VERSION "created by canmatrix"

NS_ :

BS_:

BU_: User ADM_PC_LL25 ADM_PC_BC25 ADM_PC_BP25 ADM_PC_BI25

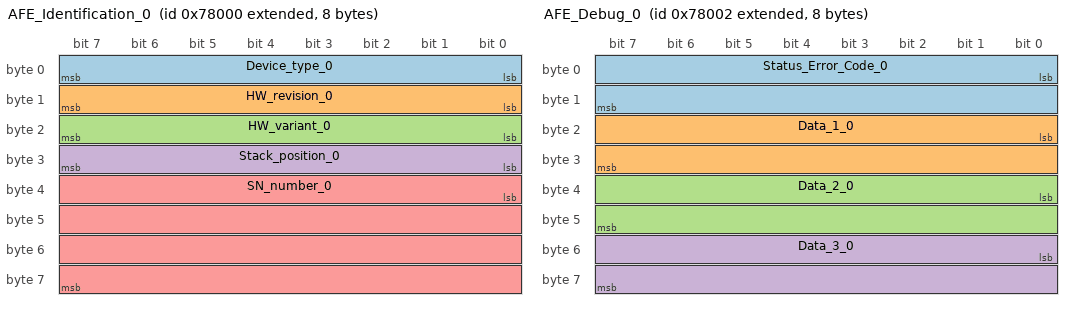
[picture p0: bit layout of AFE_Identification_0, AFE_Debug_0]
BO_ 2147975168 AFE_Identification_0: 8 ADM_PC_BP25
 SG_ Device_type_0 : 0|8@1+ (1,0) [0|255] "" Vector__XXX
 SG_ HW_revision_0 : 8|8@1+ (1,0) [0|255] "" Vector__XXX
 SG_ HW_variant_0 : 16|8@1+ (1,0) [0|255] "" Vector__XXX
 SG_ Stack_position_0 : 24|8@1+ (1,0) [0|255] "" Vector__XXX
 SG_ SN_number_0 : 32|32@1+ (1,0) [0|4294967295] "" Vector__XXX

BO_ 2147975169 AFE_FwInfo_0: 8 ADM_PC_BP25
 SG_ FW_info_mux_0 M : 56|8@1+ (1,0) [0|255] "" Vector__XXX
 SG_ FW_revision_0_0 m0 : 0|8@1+ (1,0) [0|255] "" Vector__XXX
 SG_ FW_revision_1_0 m0 : 8|8@1+ (1,0) [0|255] "" Vector__XXX
 SG_ FW_revision_2_0 m0 : 16|8@1+ (1,0) [0|255] "" Vector__XXX
 SG_ FW_revision_3_0 m0 : 24|8@1+ (1,0) [0|255] "" Vector__XXX
 SG_ FW_revision_4_0 m0 : 32|8@1+ (1,0) [0|255] "" Vector__XXX
 SG_ FW_revision_5_0 m0 : 40|8@1+ (1,0) [0|255] "" Vector__XXX
 SG_ FW_revision_6_0 m0 : 48|8@1+ (1,0) [0|255] "" Vector__XXX
 SG_ FW_revision_7_0 m1 : 0|8@1+ (1,0) [0|255] "" Vector__XXX
 SG_ FW_revision_8_0 m1 : 8|8@1+ (1,0) [0|255] "" Vector__XXX
 SG_ FW_revision_9_0 m1 : 16|8@1+ (1,0) [0|255] "" Vector__XXX
 SG_ FW_revision_10_0 m1 : 24|8@1+ (1,0) [0|255] "" Vector__XXX
 SG_ FW_revision_11_0 m1 : 32|8@1+ (1,0) [0|255] "" Vector__XXX
 SG_ FW_revision_12_0 m1 : 40|8@1+ (1,0) [0|255] "" Vector__XXX
 SG_ FW_revision_13_0 m1 : 48|8@1+ (1,0) [0|255] "" Vector__XXX
 SG_ FW_datecode_0_0 m2 : 0|8@1+ (1,0) [0|255] "" Vector__XXX
 SG_ FW_datecode_1_0 m2 : 8|8@1+ (1,0) [0|255] "" Vector__XXX
 SG_ FW_datecode_2_0 m2 : 16|8@1+ (1,0) [0|255] "" Vector__XXX
 SG_ FW_datecode_3_0 m2 : 24|8@1+ (1,0) [0|255] "" Vector__XXX
 SG_ FW_datecode_4_0 m2 : 32|8@1+ (1,0) [0|255] "" Vector__XXX
 SG_ FW_datecode_5_0 m2 : 40|8@1+ (1,0) [0|255] "" Vector__XXX
 SG_ FW_datecode_6_0 m2 : 48|8@1+ (1,0) [0|255] "" Vector__XXX
 SG_ FW_datecode_7_0 m3 : 0|8@1+ (1,0) [0|255] "" Vector__XXX
 SG_ FW_datecode_8_0 m3 : 8|8@1+ (1,0) [0|255] "" Vector__XXX
 SG_ FW_datecode_9_0 m3 : 16|8@1+ (1,0) [0|255] "" Vector__XXX
 SG_ FW_datecode_10_0 m3 : 24|8@1+ (1,0) [0|255] "" Vector__XXX
 SG_ FW_datecode_11_0 m3 : 32|8@1+ (1,0) [0|255] "" Vector__XXX
 SG_ FW_datecode_12_0 m3 : 40|8@1+ (1,0) [0|255] "" Vector__XXX
 SG_ FW_datecode_13_0 m3 : 48|8@1+ (1,0) [0|255] "" Vector__XXX

BO_ 2147975181 _AFE_Boot_FwInfo_0: 8 ADM_PC_BP25
 SG_ Boot_FW_info_mux_0 M : 56|8@1+ (1,0) [0|255] "" Vector__XXX
 SG_ FW_revision_0_0 m0 : 0|8@1+ (1,0) [0|255] "" Vector__XXX
 SG_ FW_revision_1_0 m0 : 8|8@1+ (1,0) [0|255] "" Vector__XXX
 SG_ FW_revision_2_0 m0 : 16|8@1+ (1,0) [0|255] "" Vector__XXX
 SG_ FW_revision_3_0 m0 : 24|8@1+ (1,0) [0|255] "" Vector__XXX
 SG_ FW_revision_4_0 m0 : 32|8@1+ (1,0) [0|255] "" Vector__XXX
 SG_ FW_revision_5_0 m0 : 40|8@1+ (1,0) [0|255] "" Vector__XXX
 SG_ FW_revision_6_0 m0 : 48|8@1+ (1,0) [0|255] "" Vector__XXX
 SG_ FW_revision_7_0 m1 : 0|8@1+ (1,0) [0|255] "" Vector__XXX
 SG_ FW_revision_8_0 m1 : 8|8@1+ (1,0) [0|255] "" Vector__XXX
 SG_ FW_revision_9_0 m1 : 16|8@1+ (1,0) [0|255] "" Vector__XXX
 SG_ FW_revision_10_0 m1 : 24|8@1+ (1,0) [0|255] "" Vector__XXX
 SG_ FW_revision_11_0 m1 : 32|8@1+ (1,0) [0|255] "" Vector__XXX
 SG_ FW_revision_12_0 m1 : 40|8@1+ (1,0) [0|255] "" Vector__XXX
 SG_ FW_revision_13_0 m1 : 48|8@1+ (1,0) [0|255] "" Vector__XXX
 SG_ FW_datecode_0_0 m2 : 0|8@1+ (1,0) [0|255] "" Vector__XXX
 SG_ FW_datecode_1_0 m2 : 8|8@1+ (1,0) [0|255] "" Vector__XXX
 SG_ FW_datecode_2_0 m2 : 16|8@1+ (1,0) [0|255] "" Vector__XXX
 SG_ FW_datecode_3_0 m2 : 24|8@1+ (1,0) [0|255] "" Vector__XXX
 SG_ FW_datecode_4_0 m2 : 32|8@1+ (1,0) [0|255] "" Vector__XXX
 SG_ FW_datecode_5_0 m2 : 40|8@1+ (1,0) [0|255] "" Vector__XXX
 SG_ FW_datecode_6_0 m2 : 48|8@1+ (1,0) [0|255] "" Vector__XXX
 SG_ FW_datecode_7_0 m3 : 0|8@1+ (1,0) [0|255] "" Vector__XXX
 SG_ FW_datecode_8_0 m3 : 8|8@1+ (1,0) [0|255] "" Vector__XXX
 SG_ FW_datecode_9_0 m3 : 16|8@1+ (1,0) [0|255] "" Vector__XXX
 SG_ FW_datecode_10_0 m3 : 24|8@1+ (1,0) [0|255] "" Vector__XXX
 SG_ FW_datecode_11_0 m3 : 32|8@1+ (1,0) [0|255] "" Vector__XXX
 SG_ FW_datecode_12_0 m3 : 40|8@1+ (1,0) [0|255] "" Vector__XXX
 SG_ FW_datecode_13_0 m3 : 48|8@1+ (1,0) [0|255] "" Vector__XXX

BO_ 2147975170 AFE_Debug_0: 8 ADM_PC_BP25
 SG_ Status_Error_Code_0 : 0|16@1+ (1,0) [0|65535] "" Vector__XXX
 SG_ Data_1_0 : 16|16@1+ (1,0) [0|65535] "" Vector__XXX
 SG_ Data_2_0 : 32|16@1+ (1,0) [0|65535] "" Vector__XXX
 SG_ Data_3_0 : 48|16@1+ (1,0) [0|65535] "" Vector__XXX

BO_ 2147975175 AFE_Status_0: 8 ADM_PC_BP25
 SG_ Running_0 : 0|1@1+ (1,0) [0|1] "" Vector__XXX
 SG_ PWM_0 : 1|1@1+ (1,0) [0|1] "" Vector__XXX
 SG_ Current_dc_loop_mode_0 : 2|1@1+ (1,0) [0|1] "" Vector__XXX
 SG_ Current_ac_loop_mode_0 : 3|1@1+ (1,0) [0|1] "" Vector__XXX
 SG_ Buck_0 : 5|1@1+ (1,0) [0|1] "" Vector__XXX
 SG_ Boost_0 : 6|1@1+ (1,0) [0|1] "" Vector__XXX
 SG_ Precharge_dc_buck_mode_0 : 7|1@1+ (1,0) [0|1] "" Vector__XXX
 SG_ Precharge_dc_boost_mode_0 : 8|1@1+ (1,0) [0|1] "" Vector__XXX
 SG_ Rectifier_3ph_0 : 9|1@1+ (1,0) [0|1] "" Vector__XXX
 SG_ Stack_mode_0 : 10|1@1+ (1,0) [0|1] "" Vector__XXX
 SG_ Master_0 : 11|1@1+ (1,0) [0|1] "" Vector__XXX
 SG_ Slave_0 : 12|1@1+ (1,0) [0|1] "" Vector__XXX
 SG_ Inverter_1ph_0 : 13|1@1+ (1,0) [0|1] "" Vector__XXX
 SG_ Boost_Neutral_0 : 14|1@1+ (1,0) [0|1] "" Vector__XXX
 SG_ Rectifier_1ph_0 : 15|1@1+ (1,0) [0|1] "" Vector__XXX
 SG_ Inverter_3ph_0 : 16|1@1+ (1,0) [0|1] "" Vector__XXX
 SG_ Ready_0 : 17|1@1+ (1,0) [0|1] "" Vector__XXX
 SG_ Inverter_1ph_Sync_0 : 18|1@1+ (1,0) [0|1] "" Vector__XXX
 SG_ Neutral_0 : 19|1@1+ (1,0) [0|1] "" Vector__XXX
 SG_ Rectifier_1ph_Buck_0 : 20|1@1+ (1,0) [0|1] "" Vector__XXX
 SG_ Inverter_1ph_Boost_0 : 21|1@1+ (1,0) [0|1] "" Vector__XXX
 SG_ Rectifier_distributed_0 : 22|1@1+ (1,0) [0|1] "" Vector__XXX
 SG_ MPPT_buck_0 : 23|1@1+ (1,0) [0|1] "" Vector__XXX
 SG_ MPPT_boost_0 : 24|1@1+ (1,0) [0|1] "" Vector__XXX
 SG_ Buck_2p_float_0 : 25|1@1+ (1,0) [0|1] "" Vector__XXX
 SG_ Inverter_1ph_Distributed_0 : 26|1@1+ (1,0) [0|1] "" Vector__XXX

BO_ 2147975174 AFE_Faults_0: 3 ADM_PC_BP25
 SG_ Protection_trip_internal_0 : 0|1@1+ (1,0) [0|1] "" Vector__XXX
 SG_ Protection_trip_external_0 : 1|1@1+ (1,0) [0|1] "" Vector__XXX
 SG_ Phase_U_overcurrent_0 : 2|1@1+ (1,0) [0|1] "" Vector__XXX
 SG_ Phase_U_overvoltage_0 : 3|1@1+ (1,0) [0|1] "" Vector__XXX
 SG_ Phase_U_undervoltage_0 : 4|1@1+ (1,0) [0|1] "" Vector__XXX
 SG_ Phase_V_overvoltage_0 : 5|1@1+ (1,0) [0|1] "" Vector__XXX
 SG_ Phase_V_undervoltage_0 : 6|1@1+ (1,0) [0|1] "" Vector__XXX
 SG_ Phase_V_overcurrent_0 : 7|1@1+ (1,0) [0|1] "" Vector__XXX
 SG_ Phase_W_overvoltage_0 : 8|1@1+ (1,0) [0|1] "" Vector__XXX
 SG_ Phase_W_undervoltage_0 : 9|1@1+ (1,0) [0|1] "" Vector__XXX
 SG_ Phase_W_overcurrent_0 : 10|1@1+ (1,0) [0|1] "" Vector__XXX
 SG_ DC_undervoltage_0 : 11|1@1+ (1,0) [0|1] "" Vector__XXX
 SG_ DC_overvoltage_0 : 12|1@1+ (1,0) [0|1] "" Vector__XXX
 SG_ MOSFET_overtemperature_0 : 13|1@1+ (1,0) [0|1] "" Vector__XXX
 SG_ Inductor_overtemperature_0 : 14|1@1+ (1,0) [0|1] "" Vector__XXX
 SG_ Keep_Alive_not_served_0 : 15|1@1+ (1,0) [0|1] "" Vector__XXX
 SG_ PLL_not_locked_0 : 16|1@1+ (1,0) [0|1] "" Vector__XXX
 SG_ NFO_0 : 20|1@1+ (1,0) [0|1] "" Vector__XXX
 SG_ Measurement_system_failure_0 : 21|1@1+ (1,0) [0|1] "" Vector__XXX
 SG_ EEPROM_failure_0 : 22|1@1+ (1,0) [0|1] "" Vector__XXX
 SG_ System_0 : 23|1@1+ (1,0) [0|1] "" Vector__XXX

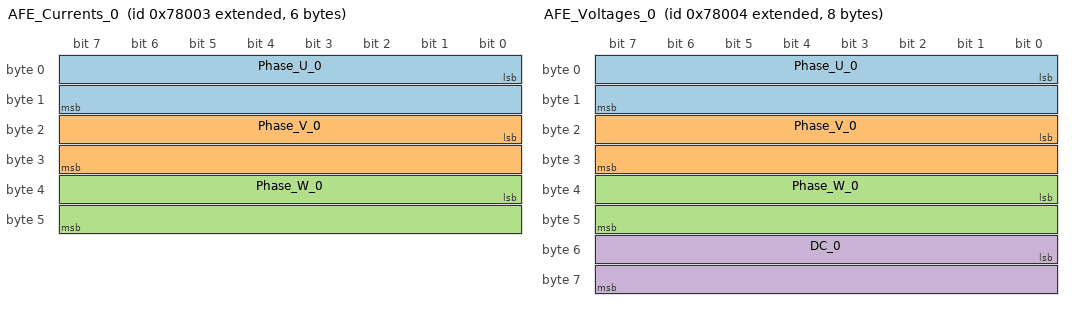
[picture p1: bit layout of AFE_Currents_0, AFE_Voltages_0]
BO_ 2147975171 AFE_Currents_0: 6 ADM_PC_BP25
 SG_ Phase_U_0 : 0|16@1- (0.01,0) [-327.68|327.67] "A" Vector__XXX
 SG_ Phase_V_0 : 16|16@1- (0.01,0) [-327.68|327.67] "A" Vector__XXX
 SG_ Phase_W_0 : 32|16@1- (0.01,0) [-327.68|327.67] "A" Vector__XXX

BO_ 2147975184 AFE_DC_Bus_current_0: 2 ADM_PC_BP25
 SG_ Bus_current_0 : 0|16@1- (0.01,0) [-327.68|327.67] "A" Vector__XXX

BO_ 2147975182 _AFE_Broadcast_0: 8 ADM_PC_BP25
 SG_ Diagnostics_Index_0 M : 56|8@1+ (1,0) [0|255] "" Vector__XXX
 SG_ Phase_U_0 m1 : 8|16@1- (0.01,0) [-327.68|327.67] "A" ADM_PC_BP25
 SG_ Phase_V_0 m1 : 24|16@1- (0.01,0) [-327.68|327.67] "A" ADM_PC_BP25
 SG_ Phase_W_0 m1 : 40|16@1- (0.01,0) [-327.68|327.67] "A" ADM_PC_BP25
 SG_ Stack_position_0 : 0|5@1+ (1,0) [0|31] "" ADM_PC_BP25
 SG_ Group_ID_0 : 5|3@1+ (1,0) [0|7] "" ADM_PC_BP25

BO_ 2147975172 AFE_Voltages_0: 8 ADM_PC_BP25
 SG_ Phase_U_0 : 0|16@1- (0.1,0) [-3276.8|3276.7] "V" Vector__XXX
 SG_ Phase_V_0 : 16|16@1- (0.1,0) [-3276.8|3276.7] "V" Vector__XXX
 SG_ Phase_W_0 : 32|16@1- (0.1,0) [-3276.8|3276.7] "V" Vector__XXX
 SG_ DC_0 : 48|16@1- (0.1,0) [-3276.8|3276.7] "V" Vector__XXX

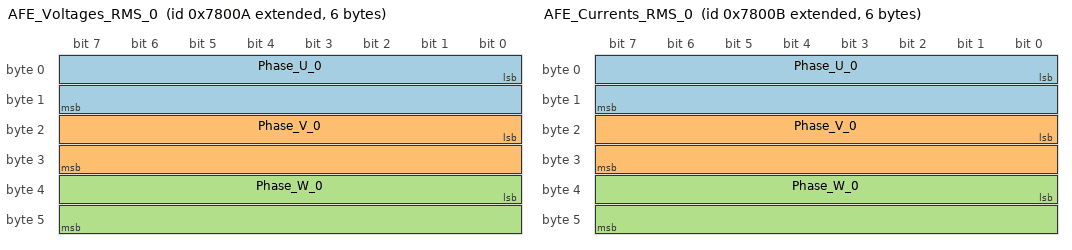
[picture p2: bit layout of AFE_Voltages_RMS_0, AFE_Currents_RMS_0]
BO_ 2147975178 AFE_Voltages_RMS_0: 6 ADM_PC_BP25
 SG_ Phase_U_0 : 0|16@1+ (0.1,0) [0|6553.5] "V" Vector__XXX
 SG_ Phase_V_0 : 16|16@1+ (0.1,0) [0|6553.5] "V" Vector__XXX
 SG_ Phase_W_0 : 32|16@1+ (0.1,0) [0|6553.5] "V" Vector__XXX

BO_ 2147975179 AFE_Currents_RMS_0: 6 ADM_PC_BP25
 SG_ Phase_U_0 : 0|16@1+ (0.01,0) [0.00|655.35] "A" Vector__XXX
 SG_ Phase_V_0 : 16|16@1+ (0.01,0) [0.00|655.35] "A" Vector__XXX
 SG_ Phase_W_0 : 32|16@1+ (0.01,0) [0.00|655.35] "A" Vector__XXX

BO_ 2147975180 AFE_Mains_0: 4 ADM_PC_BP25
 SG_ Frequency_0 : 0|16@1+ (0.01,0) [0.00|655.35] "Hz" Vector__XXX
 SG_ Phase_0 : 16|16@1- (0.1,0) [-3276.8|3276.7] "Deg." Vector__XXX

BO_ 2147975173 AFE_Temperatures_0: 4 ADM_PC_BP25
 SG_ Temp_Bridge_0 : 0|16@1- (0.01,0) [-327.68|327.67] "°C" Vector__XXX
 SG_ Temp_Inductors_0 : 16|16@1- (0.01,0) [-327.68|327.67] "°C" Vector__XXX

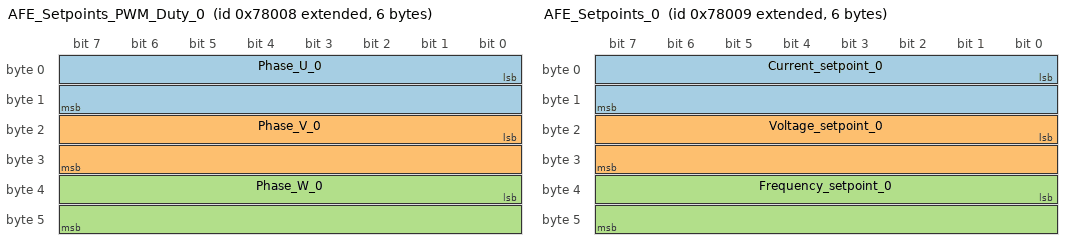
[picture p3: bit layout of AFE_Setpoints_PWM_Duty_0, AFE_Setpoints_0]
BO_ 2147975176 AFE_Setpoints_PWM_Duty_0: 6 ADM_PC_BP25
 SG_ Phase_U_0 : 0|16@1+ (0.001525902,0) [0E-009|99.999987570] "%" Vector__XXX
 SG_ Phase_V_0 : 16|16@1+ (0.001525902,0) [0E-009|99.999987570] "%" Vector__XXX
 SG_ Phase_W_0 : 32|16@1+ (0.001525902,0) [0E-009|99.999987570] "%" Vector__XXX

BO_ 2147975177 AFE_Setpoints_0: 6 ADM_PC_BP25
 SG_ Current_setpoint_0 : 0|16@1- (0.01,0) [-327.68|327.67] "A" Vector__XXX
 SG_ Voltage_setpoint_0 : 16|16@1+ (0.1,0) [0|6553.5] "V" Vector__XXX
 SG_ Frequency_setpoint_0 : 32|16@1+ (0.01,0) [0.00|655.35] "Hz" Vector__XXX

BO_ 2147942496 AFE_Keep_Alive_0: 1 User
 SG_ Keep_Alive_Enable_0 : 0|1@1+ (1,0) [0|1] "" ADM_PC_BP25

BO_ 2147942464 AFE_Mode_Control_0: 8 User
 SG_ Converter_ON_0 : 0|1@1+ (1,0) [0|1] "" ADM_PC_BP25
 SG_ PWM_ON_0 : 1|1@1+ (1,0) [0|1] "" ADM_PC_BP25
 SG_ DC_Current_feedback_ON_0 : 2|1@1+ (1,0) [0|1] "" ADM_PC_BP25
 SG_ AC_Current_feedback_ON_0 : 3|1@1+ (1,0) [0|1] "" ADM_PC_BP25
 SG_ Buck_ON_0 : 5|1@1+ (1,0) [0|1] "" ADM_PC_BP25
 SG_ Boost_ON_0 : 6|1@1+ (1,0) [0|1] "" ADM_PC_BP25
 SG_ Rectifier_3ph_ON_0 : 9|1@1+ (1,0) [0|1] "" ADM_PC_BP25
 SG_ Inverter_1ph_ON_0 : 10|1@1+ (1,0) [0|1] "" ADM_PC_BP25
 SG_ Rectifier_1ph_ON_0 : 11|1@1+ (1,0) [0|1] "" ADM_PC_BP25
 SG_ Boost_Neutral_ON_0 : 12|1@1+ (1,0) [0|1] "" ADM_PC_BP25
 SG_ Inverter_3ph_ON_0 : 13|1@1+ (1,0) [0|1] "" ADM_PC_BP25
 SG_ Inverter_1ph_Sync_ON_0 : 14|1@1+ (1,0) [0|1] "" ADM_PC_BP25
 SG_ Neutral_ON_0 : 15|1@1+ (1,0) [0|1] "" ADM_PC_BP25
 SG_ Rectifier_1ph_Buck_ON_0 : 16|1@1+ (1,0) [0|1] "" ADM_PC_BP25
 SG_ Inverter_1ph_Boost_ON_0 : 17|1@1+ (1,0) [0|1] "" ADM_PC_BP25
 SG_ Rectifier_Distributed_ON_0 : 18|1@1+ (1,0) [0|1] "" ADM_PC_BP25
 SG_ MPPT_buck_ON_0 : 19|1@1+ (1,0) [0|1] "" ADM_PC_BP25
 SG_ MPPT_boost_ON_0 : 20|1@1+ (1,0) [0|1] "" ADM_PC_BP25
 SG_ Buck_2p_float_ON_0 : 21|1@1+ (1,0) [0|1] "" ADM_PC_BP25
 SG_ Inverter_1ph_Distributed_ON_0 : 22|1@1+ (1,0) [0|1] "" ADM_PC_BP25

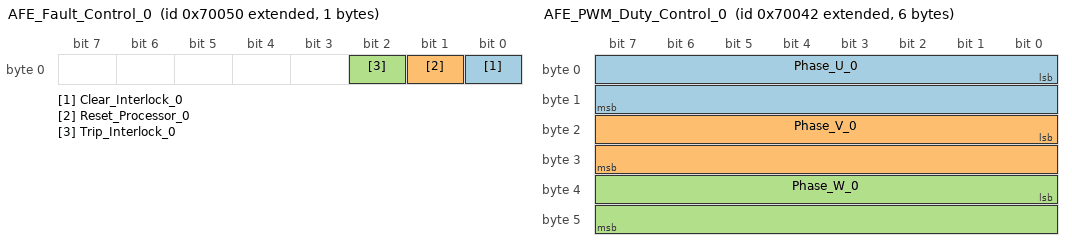
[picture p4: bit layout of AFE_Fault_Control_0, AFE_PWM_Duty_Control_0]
BO_ 2147942480 AFE_Fault_Control_0: 1 User
 SG_ Clear_Interlock_0 : 0|1@1+ (1,0) [0|1] "" ADM_PC_BP25
 SG_ Reset_Processor_0 : 1|1@1+ (1,0) [0|1] "" ADM_PC_BP25
 SG_ Trip_Interlock_0 : 2|1@1+ (1,0) [0|1] "" ADM_PC_BP25

BO_ 2147942465 AFE_Reactive_Current_Setpoint_Co: 2 User
 SG_ Reactive_current_setpoint_0 : 0|16@1- (0.01,0) [-150|150] "A" ADM_PC_BP25

BO_ 2147942466 AFE_PWM_Duty_Control_0: 6 User
 SG_ Phase_U_0 : 0|16@1+ (0.001525902,0) [0E-009|99.999987570] "%" ADM_PC_BP25
 SG_ Phase_V_0 : 16|16@1+ (0.001525902,0) [0E-009|99.999987570] "%" ADM_PC_BP25
 SG_ Phase_W_0 : 32|16@1+ (0.001525902,0) [0E-009|99.999987570] "%" ADM_PC_BP25

BO_ 2147942467 AFE_Current_Setpoint_Control_0: 2 User
 SG_ Current_setpoint_0 : 0|16@1- (0.01,0) [-150|150] "A" ADM_PC_BP25

BO_ 2147942468 AFE_Voltage_Setpoint_Control_0: 2 User
 SG_ Voltage_setpoint_0 : 0|16@1+ (0.1,0) [0|1500] "V" ADM_PC_BP25

BO_ 2147942472 AFE_Frequency_Setpoint_Control_0: 2 User
 SG_ Frequency_setpoint_0 : 0|16@1+ (0.01,0) [40|70] "Hz" ADM_PC_BP25

BO_ 2147942473 AFE_Phase_Setpoint_Control_0: 2 User
 SG_ Phase_setpoint_0 : 0|16@1+ (1,0) [0|360] "deg" ADM_PC_BP25

BO_ 2147942512 AFE_Rectifier_Setpoint_Control_0: 8 User
 SG_ Voltage_setpoint_2_0 : 0|16@1+ (0.1,0) [0|1500] "V" ADM_PC_BP25
 SG_ Current_setpoint_2_0 : 16|16@1- (0.01,0) [-150|150] "A" ADM_PC_BP25

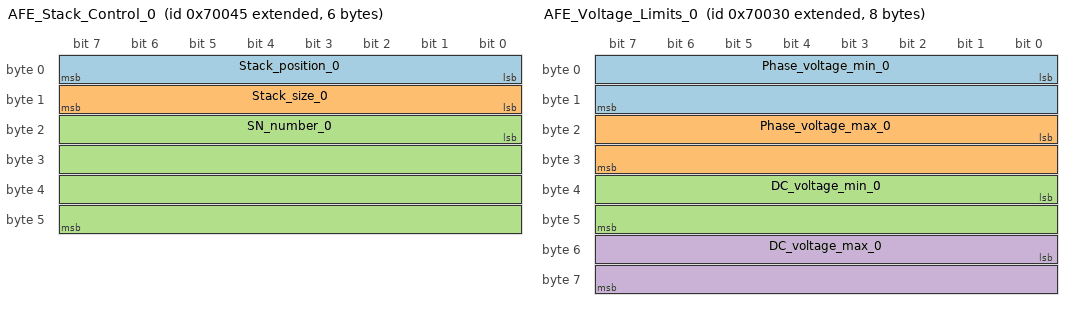
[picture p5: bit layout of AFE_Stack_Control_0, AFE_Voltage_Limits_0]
BO_ 2147942469 AFE_Stack_Control_0: 6 User
 SG_ Stack_position_0 : 0|8@1+ (1,0) [0|255] "" ADM_PC_BP25
 SG_ Stack_size_0 : 8|8@1+ (1,0) [0|255] "" ADM_PC_BP25
 SG_ SN_number_0 : 16|32@1+ (1,0) [0|4294967295] "" ADM_PC_BP25

BO_ 2147942448 AFE_Voltage_Limits_0: 8 User
 SG_ Phase_voltage_min_0 : 0|16@1- (0.1,0) [0|3276.7] "V" ADM_PC_BP25
 SG_ Phase_voltage_max_0 : 16|16@1- (0.1,0) [-3276.8|850] "V" ADM_PC_BP25
 SG_ DC_voltage_min_0 : 32|16@1- (0.1,0) [0|3276.7] "V" ADM_PC_BP25
 SG_ DC_voltage_max_0 : 48|16@1- (0.1,0) [-3276.8|850] "V" ADM_PC_BP25

BO_ 2147942449 AFE_Current_Limits_0: 4 User
 SG_ Phase_current_min_0 : 0|16@1- (0.01,0) [-60|60] "A" ADM_PC_BP25
 SG_ Phase_current_max_0 : 16|16@1- (0.01,0) [-60|60] "A" ADM_PC_BP25

BO_ 2147942476 AFE_Group_Control_0: 1 User
 SG_ Group_ID_0 : 0|8@1+ (1,0) [0|255] "" ADM_PC_BP25

BO_ 2147975183 AFE_Group_Info_0: 1 ADM_PC_BP25
 SG_ Group_ID_0 : 0|8@1+ (1,0) [0|255] "" Vector__XXX

BO_ 2147942497 AFE_System_Flags_Control_0: 8 User
 SG_ Factory_mode_0 : 0|1@1+ (1,0) [0|1] "" ADM_PC_BP25
 SG_ Silent_CAN_mode_0 : 1|1@1+ (1,0) [0|1] "" ADM_PC_BP25

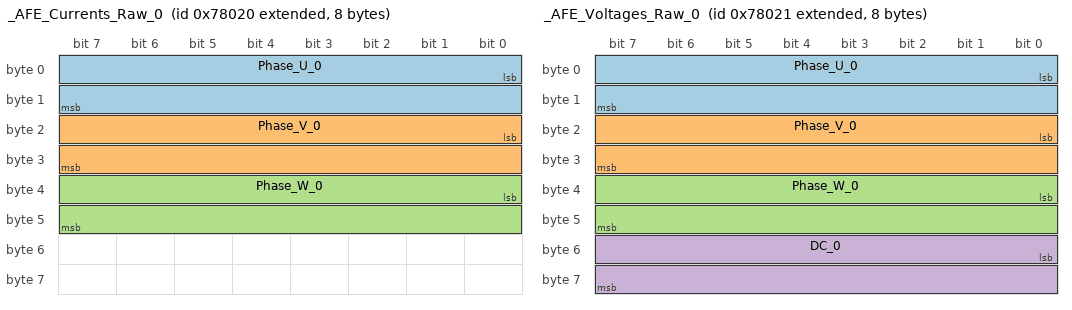
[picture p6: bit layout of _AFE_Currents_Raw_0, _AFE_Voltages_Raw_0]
BO_ 2147975200 _AFE_Currents_Raw_0: 8 ADM_PC_BP25
 SG_ Phase_U_0 : 0|16@1- (1,0) [-32768|32767] "" Vector__XXX
 SG_ Phase_V_0 : 16|16@1- (1,0) [-32768|32767] "" Vector__XXX
 SG_ Phase_W_0 : 32|16@1- (1,0) [-32768|32767] "" Vector__XXX

BO_ 2147975201 _AFE_Voltages_Raw_0: 8 ADM_PC_BP25
 SG_ Phase_U_0 : 0|16@1- (1,0) [-32768|32767] "" Vector__XXX
 SG_ Phase_V_0 : 16|16@1- (1,0) [-32768|32767] "" Vector__XXX
 SG_ Phase_W_0 : 32|16@1- (1,0) [-32768|32767] "" Vector__XXX
 SG_ DC_0 : 48|16@1- (1,0) [-32768|32767] "" Vector__XXX

BO_ 2147942474 _AFE_ADC_Calibration_Mode_0: 1 User
 SG_ Calibration_Index_0 M : 2|5@1+ (1,0) [0|31] "" Vector__XXX
 SG_ Current_U_0 m1 : 0|2@1+ (1,0) [0|3] "" ADM_PC_BP25
 SG_ Current_V_0 m2 : 0|2@1+ (1,0) [0|3] "" ADM_PC_BP25
 SG_ Current_W_0 m3 : 0|2@1+ (1,0) [0|3] "" ADM_PC_BP25
 SG_ Voltage_U_0 m4 : 0|2@1+ (1,0) [0|3] "" ADM_PC_BP25
 SG_ Voltage_V_0 m5 : 0|2@1+ (1,0) [0|3] "" ADM_PC_BP25
 SG_ Voltage_W_0 m6 : 0|2@1+ (1,0) [0|3] "" ADM_PC_BP25
 SG_ Voltage_DC_0 m7 : 0|2@1+ (1,0) [0|3] "" ADM_PC_BP25
 SG_ start_0 : 7|1@1+ (1,0) [0|1] "" ADM_PC_BP25

BO_ 2147942475 _AFE_ADC_Calibration_Setpoint_0: 3 User
 SG_ Calibration_Index_0 M : 16|5@1+ (1,0) [0|31] "" Vector__XXX
 SG_ Current_U_0 m1 : 0|16@1- (0.01,0) [-100|100] "A" ADM_PC_BP25
 SG_ Current_V_0 m2 : 0|16@1- (0.01,0) [-100|100] "A" ADM_PC_BP25
 SG_ Current_W_0 m3 : 0|16@1- (0.01,0) [-100|100] "A" ADM_PC_BP25
 SG_ Voltage_U_0 m4 : 0|16@1+ (0.1,0) [0|1500] "V" ADM_PC_BP25
 SG_ Voltage_V_0 m5 : 0|16@1+ (0.1,0) [0|1500] "V" ADM_PC_BP25
 SG_ Voltage_W_0 m6 : 0|16@1+ (0.1,0) [0|1500] "V" ADM_PC_BP25
 SG_ Voltage_DC_0 m7 : 0|16@1+ (0.1,0) [0|1500] "V" ADM_PC_BP25
 SG_ point_0 : 21|3@1+ (1,0) [0|7] "" ADM_PC_BP25

BO_ 2147942470 _AFE_Calibration_Offset_Update_0: 6 User
 SG_ Calibration_Index_0 M : 16|16@1+ (1,0) [0|65535] "" Vector__XXX
 SG_ Current_U_0 m0 : 0|16@1- (1,0) [-32768|32767] "ADC Counts" ADM_PC_BP25
 SG_ Current_V_0 m1 : 0|16@1- (1,0) [-32768|32767] "ADC Counts" ADM_PC_BP25
 SG_ Current_W_0 m2 : 0|16@1- (1,0) [-32768|32767] "ADC Counts" ADM_PC_BP25
 SG_ Voltage_U_0 m3 : 0|16@1- (1,0) [-32768|32767] "ADC Counts" ADM_PC_BP25
 SG_ Voltage_V_0 m4 : 0|16@1- (1,0) [-32768|32767] "ADC Counts" ADM_PC_BP25
 SG_ Voltage_W_0 m5 : 0|16@1- (1,0) [-32768|32767] "ADC Counts" ADM_PC_BP25
 SG_ Voltage_DC_0 m6 : 0|16@1- (1,0) [-32768|32767] "ADC Counts" ADM_PC_BP25
 SG_ CRC_0 : 32|16@1+ (1,0) [0|65535] "-" ADM_PC_BP25

BO_ 2147942471 _AFE_Calibration_Scale_Update_0: 6 User
 SG_ Calibration_Index_0 M : 16|16@1+ (1,0) [0|65535] "" Vector__XXX
 SG_ Current_U_0 m0 : 0|16@1- (0.0000152587890625,0) [-0.5000000000000000|0.4999847412109375] "scale = 1.0 + value" ADM_PC_BP25
 SG_ Current_V_0 m1 : 0|16@1- (0.0000152587890625,0) [-0.5000000000000000|0.4999847412109375] "scale = 1.0 + value" ADM_PC_BP25
 SG_ Current_W_0 m2 : 0|16@1- (0.0000152587890625,0) [-0.5000000000000000|0.4999847412109375] "scale = 1.0 + value" ADM_PC_BP25
 SG_ Voltage_U_0 m3 : 0|16@1- (0.0000152587890625,0) [-0.5000000000000000|0.4999847412109375] "scale = 1.0 + value" ADM_PC_BP25
 SG_ Voltage_V_0 m4 : 0|16@1- (0.0000152587890625,0) [-0.5000000000000000|0.4999847412109375] "scale = 1.0 + value" ADM_PC_BP25
 SG_ Voltage_W_0 m5 : 0|16@1- (0.0000152587890625,0) [-0.5000000000000000|0.4999847412109375] "scale = 1.0 + value" ADM_PC_BP25
 SG_ Voltage_DC_0 m6 : 0|16@1- (0.0000152587890625,0) [-0.5000000000000000|0.4999847412109375] "scale = 1.0 + value" ADM_PC_BP25
 SG_ CRC_0 : 32|16@1+ (1,0) [0|65535] "-" ADM_PC_BP25

BO_ 2147975249 _AFE_Calibration_Adc_Scale_0: 6 ADM_PC_BP25
 SG_ Adc_Index_0 M : 32|16@1+ (1,0) [0|65535] "" Vector__XXX
 SG_ Current_U_0 m0 : 0|32@1+ (1,0) [0|4294967295] "1 / adc_bins" User
 SG_ Current_V_0 m1 : 0|32@1+ (1,0) [0|4294967295] "1 / adc_bins" User
 SG_ Current_W_0 m2 : 0|32@1+ (1,0) [0|4294967295] "1 / adc_bins" User
 SG_ Voltage_U_0 m3 : 0|32@1+ (1,0) [0|4294967295] "1 / adc_bins" User
 SG_ Voltage_V_0 m4 : 0|32@1+ (1,0) [0|4294967295] "1 / adc_bins" User
 SG_ Voltage_W_0 m5 : 0|32@1+ (1,0) [0|4294967295] "1 / adc_bins" User
 SG_ Voltage_DC_0 m6 : 0|32@1+ (1,0) [0|4294967295] "1 / adc_bins" User

BO_ 2147975250 _AFE_Calibration_Adc_Fs_0: 6 ADM_PC_BP25
 SG_ Adc_Index_0 M : 32|16@1+ (1,0) [0|65535] "" Vector__XXX
 SG_ Current_U_0 m0 : 0|32@1+ (1,0) [0|4294967295] "Fullscale" User
 SG_ Current_V_0 m1 : 0|32@1+ (1,0) [0|4294967295] "Fullscale" User
 SG_ Current_W_0 m2 : 0|32@1+ (1,0) [0|4294967295] "Fullscale" User
 SG_ Voltage_U_0 m3 : 0|32@1+ (1,0) [0|4294967295] "Fullscale" User
 SG_ Voltage_V_0 m4 : 0|32@1+ (1,0) [0|4294967295] "Fullscale" User
 SG_ Voltage_W_0 m5 : 0|32@1+ (1,0) [0|4294967295] "Fullscale" User
 SG_ Voltage_DC_0 m6 : 0|32@1+ (1,0) [0|4294967295] "Fullscale" User

BO_ 2147975251 _AFE_Calibration_Adc_Offset_0: 4 ADM_PC_BP25
 SG_ Adc_Index_0 M : 16|16@1+ (1,0) [0|65535] "" Vector__XXX
 SG_ Current_U_0 m0 : 0|16@1- (1,0) [-32768|32767] "-" User
 SG_ Current_V_0 m1 : 0|16@1- (1,0) [-32768|32767] "-" User
 SG_ Current_W_0 m2 : 0|16@1- (1,0) [-32768|32767] "-" User
 SG_ Voltage_U_0 m3 : 0|16@1- (1,0) [-32768|32767] "-" User
 SG_ Voltage_V_0 m4 : 0|16@1- (1,0) [-32768|32767] "-" User
 SG_ Voltage_W_0 m5 : 0|16@1- (1,0) [-32768|32767] "-" User
 SG_ Voltage_DC_0 m6 : 0|16@1- (1,0) [-32768|32767] "-" User

BO_ 2147975252 _AFE_Calibration_Adc_Gain_0: 4 ADM_PC_BP25
 SG_ Adc_Index_0 M : 16|16@1+ (1,0) [0|65535] "" Vector__XXX
 SG_ Current_U_0 m0 : 0|16@1- (1,0) [-32768|32767] "-" User
 SG_ Current_V_0 m1 : 0|16@1- (1,0) [-32768|32767] "-" User
 SG_ Current_W_0 m2 : 0|16@1- (1,0) [-32768|32767] "-" User
 SG_ Voltage_U_0 m3 : 0|16@1- (1,0) [-32768|32767] "-" User
 SG_ Voltage_V_0 m4 : 0|16@1- (1,0) [-32768|32767] "-" User
 SG_ Voltage_W_0 m5 : 0|16@1- (1,0) [-32768|32767] "-" User
 SG_ Voltage_DC_0 m6 : 0|16@1- (1,0) [-32768|32767] "-" User

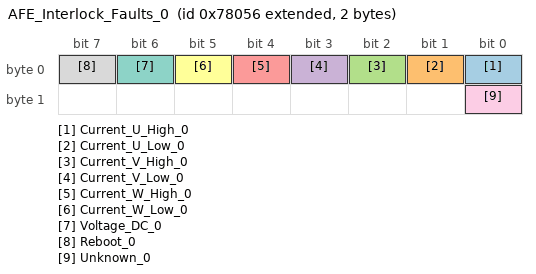
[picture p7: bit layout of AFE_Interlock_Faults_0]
BO_ 2147975254 AFE_Interlock_Faults_0: 2 ADM_PC_BP25
 SG_ Current_U_High_0 : 0|1@1+ (1,0) [0|1] "" Vector__XXX
 SG_ Current_U_Low_0 : 1|1@1+ (1,0) [0|1] "" Vector__XXX
 SG_ Current_V_High_0 : 2|1@1+ (1,0) [0|1] "" Vector__XXX
 SG_ Current_V_Low_0 : 3|1@1+ (1,0) [0|1] "" Vector__XXX
 SG_ Current_W_High_0 : 4|1@1+ (1,0) [0|1] "" Vector__XXX
 SG_ Current_W_Low_0 : 5|1@1+ (1,0) [0|1] "" Vector__XXX
 SG_ Voltage_DC_0 : 6|1@1+ (1,0) [0|1] "" Vector__XXX
 SG_ Reboot_0 : 7|1@1+ (1,0) [0|1] "" Vector__XXX
 SG_ Unknown_0 : 8|1@1+ (1,0) [0|1] "" Vector__XXX

BO_TX_BU_ 2147942464 : User,ADM_PC_LL25,ADM_PC_BC25,ADM_PC_BI25;
BO_TX_BU_ 2147942467 : User,ADM_PC_LL25,ADM_PC_BC25,ADM_PC_BI25;
BO_TX_BU_ 2147942468 : User,ADM_PC_LL25,ADM_PC_BC25,ADM_PC_BI25;
CM_ BO_ 2147975168  "Identification of the device";
CM_ BO_ 2147975169  "Git revision of the DSP firmware";
CM_ BO_ 2147975181  "Git revision of the bootloader firmware.";
CM_ BO_ 2147975170  "Values for debugging of HW/SW problems";
CM_ BO_ 2147975175  "Status bitfield";
CM_ BO_ 2147975174  "Fault bitfield";
CM_ BO_ 2147975171  "Current of phases U, V, W";
CM_ BO_ 2147975184  "Current of of the DC Bus";
CM_ BO_ 2147975182  "All AFEs will listen to this message";
CM_ BO_ 2147975179  "RMS Current of phases U, V, W";
CM_ BO_ 2147975180  "Three-Phase mains health (frequency, phase...)";
CM_ BO_ 2147975173  "Readouts of the module temperature sensors";
CM_ BO_ 2147975176  "Setpoints";
CM_ BO_ 2147975177  "Setpoints";
CM_ BO_ 2147942496  "Keep alive ping message. ";
CM_ BO_ 2147942464  "Operation Mode control: sets the converter operation mode";
CM_ BO_ 2147942480  "Fault Control: actions to clear faults and reset the system";
CM_ BO_ 2147942465  "Reactive power setpoint control.";
CM_ BO_ 2147942466  "PWM duty cycle control";
CM_ BO_ 2147942467  "Current setpoint control";
CM_ BO_ 2147942468  "Voltage setpoint control";
CM_ BO_ 2147942472  "Frequency setpoint control";
CM_ BO_ 2147942473  "Phase setpoint control";
CM_ BO_ 2147942512  "Additional voltage and current setpoints in single-phase rectifier and inverter control modes.";
CM_ BO_ 2147942469  "PFC stack control";
CM_ BO_ 2147942448  "Set the input and output voltage limits (minimum and maximum)";
CM_ BO_ 2147942449  "Set the output current limits (mminimum and maximum)";
CM_ BO_ 2147942476  "Set the Group ID of the device";
CM_ BO_ 2147975183  "Contains the Group ID of the device";
CM_ BO_ 2147942497  "Control the system flags";
CM_ BO_ 2147975200  "Current of phases A and B";
CM_ BO_ 2147975201  "Current of phases A and B";
CM_ BO_ 2147942474  "Automatic ADC calibration.";
CM_ BO_ 2147942475  "Setpoint for automatic ADC calibration.";
CM_ BO_ 2147942470  "Update of the calibration table for offsets.";
CM_ BO_ 2147942471  "Update of the calibration table for scales.";
CM_ BO_ 2147975249  "
                Adc scale (resolution) value of readouts.
            ";
CM_ BO_ 2147975250  "
                Adc fullscale value of readouts.
            ";
CM_ BO_ 2147975251  "
                Readout of ADC calibration data (offset) from EEPROM.
            ";
CM_ BO_ 2147975252  "
                Readout of ADC calibration data (gain) from EEPROM.
            ";
CM_ BO_ 2147975254  "Fault bitfield";

CM_ SG_ 2147975168 Device_type_0 "The device identification field, uniquely identifies the sender in the network";
CM_ SG_ 2147975168 HW_revision_0 "The hardware revision number";
CM_ SG_ 2147975168 HW_variant_0 "The DSP firmware revision number";
CM_ SG_ 2147975168 Stack_position_0 "Position of the module within the stack";
CM_ SG_ 2147975168 SN_number_0 "Unique module serial number";
CM_ SG_ 2147975169 FW_revision_0_0 "Character 0";
CM_ SG_ 2147975169 FW_revision_1_0 "Character 1";
CM_ SG_ 2147975169 FW_revision_2_0 "Character 2";
CM_ SG_ 2147975169 FW_revision_3_0 "Character 3";
CM_ SG_ 2147975169 FW_revision_4_0 "Character 3";
CM_ SG_ 2147975169 FW_revision_5_0 "Character 3";
CM_ SG_ 2147975169 FW_revision_6_0 "Character 3";
CM_ SG_ 2147975169 FW_revision_7_0 "Character 7";
CM_ SG_ 2147975169 FW_revision_8_0 "Character 8";
CM_ SG_ 2147975169 FW_revision_9_0 "Character 9";
CM_ SG_ 2147975169 FW_revision_10_0 "Character 10";
CM_ SG_ 2147975169 FW_revision_11_0 "Character 11";
CM_ SG_ 2147975169 FW_revision_12_0 "Character 12";
CM_ SG_ 2147975169 FW_revision_13_0 "Character 13";
CM_ SG_ 2147975169 FW_datecode_0_0 "Character 0";
CM_ SG_ 2147975169 FW_datecode_1_0 "Character 1";
CM_ SG_ 2147975169 FW_datecode_2_0 "Character 2";
CM_ SG_ 2147975169 FW_datecode_3_0 "Character 3";
CM_ SG_ 2147975169 FW_datecode_4_0 "Character 3";
CM_ SG_ 2147975169 FW_datecode_5_0 "Character 3";
CM_ SG_ 2147975169 FW_datecode_6_0 "Character 3";
CM_ SG_ 2147975169 FW_datecode_7_0 "Character 7";
CM_ SG_ 2147975169 FW_datecode_8_0 "Character 8";
CM_ SG_ 2147975169 FW_datecode_9_0 "Character 9";
CM_ SG_ 2147975169 FW_datecode_10_0 "Character 10";
CM_ SG_ 2147975169 FW_datecode_11_0 "Character 11";
CM_ SG_ 2147975169 FW_datecode_12_0 "Character 12";
CM_ SG_ 2147975169 FW_datecode_13_0 "Character 13";
CM_ SG_ 2147975181 FW_revision_0_0 "Character 0";
CM_ SG_ 2147975181 FW_revision_1_0 "Character 1";
CM_ SG_ 2147975181 FW_revision_2_0 "Character 2";
CM_ SG_ 2147975181 FW_revision_3_0 "Character 3";
CM_ SG_ 2147975181 FW_revision_4_0 "Character 3";
CM_ SG_ 2147975181 FW_revision_5_0 "Character 3";
CM_ SG_ 2147975181 FW_revision_6_0 "Character 3";
CM_ SG_ 2147975181 FW_revision_7_0 "Character 7";
CM_ SG_ 2147975181 FW_revision_8_0 "Character 8";
CM_ SG_ 2147975181 FW_revision_9_0 "Character 9";
CM_ SG_ 2147975181 FW_revision_10_0 "Character 10";
CM_ SG_ 2147975181 FW_revision_11_0 "Character 11";
CM_ SG_ 2147975181 FW_revision_12_0 "Character 12";
CM_ SG_ 2147975181 FW_revision_13_0 "Character 13";
CM_ SG_ 2147975181 FW_datecode_0_0 "Character 0";
CM_ SG_ 2147975181 FW_datecode_1_0 "Character 1";
CM_ SG_ 2147975181 FW_datecode_2_0 "Character 2";
CM_ SG_ 2147975181 FW_datecode_3_0 "Character 3";
CM_ SG_ 2147975181 FW_datecode_4_0 "Character 3";
CM_ SG_ 2147975181 FW_datecode_5_0 "Character 3";
CM_ SG_ 2147975181 FW_datecode_6_0 "Character 3";
CM_ SG_ 2147975181 FW_datecode_7_0 "Character 7";
CM_ SG_ 2147975181 FW_datecode_8_0 "Character 8";
CM_ SG_ 2147975181 FW_datecode_9_0 "Character 9";
CM_ SG_ 2147975181 FW_datecode_10_0 "Character 10";
CM_ SG_ 2147975181 FW_datecode_11_0 "Character 11";
CM_ SG_ 2147975181 FW_datecode_12_0 "Character 12";
CM_ SG_ 2147975181 FW_datecode_13_0 "Character 13";
CM_ SG_ 2147975170 Status_Error_Code_0 "Main status / error code as defined in errno/errno.h";
CM_ SG_ 2147975170 Data_1_0 "Additional information for the error/status";
CM_ SG_ 2147975170 Data_2_0 "Additional information for the error/status";
CM_ SG_ 2147975170 Data_3_0 "Additional information for the error/status";
CM_ SG_ 2147975175 Running_0 "Indicates if converter is running.";
CM_ SG_ 2147975175 PWM_0 "Indicates if converter is in PWM control mode.";
CM_ SG_ 2147975175 Current_dc_loop_mode_0 "Indicates if the current DC loop is enabled.";
CM_ SG_ 2147975175 Current_ac_loop_mode_0 "Indicates if the current AC loop is enabled.";
CM_ SG_ 2147975175 Buck_0 "Indicates if converter is in buck control mode.";
CM_ SG_ 2147975175 Boost_0 "Indicates if converter is in boost control mode.";
CM_ SG_ 2147975175 Precharge_dc_buck_mode_0 "Indicates if the precharge DC mode is enabled - buck direction.";
CM_ SG_ 2147975175 Precharge_dc_boost_mode_0 "Indicates if the precharge DC mode is enabled - boost direction.";
CM_ SG_ 2147975175 Rectifier_3ph_0 "Indicates if converter is in three-phase rectifier control mode.";
CM_ SG_ 2147975175 Stack_mode_0 "Indicates if converter is operating in stack mode.";
CM_ SG_ 2147975175 Master_0 "Indicates if converter is master in the stack.";
CM_ SG_ 2147975175 Slave_0 "Indicates if converter is slave in the stack.";
CM_ SG_ 2147975175 Inverter_1ph_0 "Indicates if converter is in single-phase inverter control mode.";
CM_ SG_ 2147975175 Boost_Neutral_0 "Indicates if converter is in boost control mode with neutral generation.";
CM_ SG_ 2147975175 Rectifier_1ph_0 "Indicates if converter is in single-phase rectifier control mode.";
CM_ SG_ 2147975175 Inverter_3ph_0 "Indicates if converter is in three-phase inverter control mode.";
CM_ SG_ 2147975175 Ready_0 "Indicates if converter is ready for operation.";
CM_ SG_ 2147975175 Inverter_1ph_Sync_0 "Single-phase inverter control mode with phase synchronization.";
CM_ SG_ 2147975175 Neutral_0 "Open-loop neutral generation.";
CM_ SG_ 2147975175 Rectifier_1ph_Buck_0 "Single-phase rectifier with buck on one leg.";
CM_ SG_ 2147975175 Inverter_1ph_Boost_0 "Single-phase inverter with boost on one leg.";
CM_ SG_ 2147975175 Rectifier_distributed_0 "Not available at the moment";
CM_ SG_ 2147975175 MPPT_buck_0 "Not available at the moment";
CM_ SG_ 2147975175 MPPT_boost_0 "Not available at the moment";
CM_ SG_ 2147975175 Buck_2p_float_0 "Buck in phases L1 and L2. Phase L3 is left floating (high impedance)";
CM_ SG_ 2147975175 Inverter_1ph_Distributed_0 "Single-phase inverter mode  distributed";
CM_ SG_ 2147975174 Protection_trip_internal_0 "This flagg is asserted if the interlock is open due to an internal fault condition (self-protection)";
CM_ SG_ 2147975174 Protection_trip_external_0 "This flag is asserted if the interlock is open due to an external condition received in the module.";
CM_ SG_ 2147975174 Phase_U_overcurrent_0 "Indicates an overcurrent event on Phase U. The overcurrent event is triggered when the measured phase current is over the programmed current limit.";
CM_ SG_ 2147975174 Phase_U_overvoltage_0 "Indicates an overvoltage event on Phase U. The overvoltage event is triggered when the measured phase voltage is over the programmed voltage limit.";
CM_ SG_ 2147975174 Phase_U_undervoltage_0 "Indicates an undervoltage event on Phase U. The overvoltage event is triggered when the measured phase voltage is over the programmed voltage limit.";
CM_ SG_ 2147975174 Phase_V_overvoltage_0 "Indicates an overvoltage event on Phase V. The overvoltage event is triggered when the measured phase voltage is over the programmed voltage limit.";
CM_ SG_ 2147975174 Phase_V_undervoltage_0 "Indicates an undervoltage event on Phase U. The overvoltage event is triggered when the measured phase voltage is over the programmed voltage limit.";
CM_ SG_ 2147975174 Phase_V_overcurrent_0 "Indicates an overcurrent event on Phase U. The overcurrent event is triggered when the measured phase current is over the programmed current limit.";
CM_ SG_ 2147975174 Phase_W_overvoltage_0 "Indicates an overvoltage event on Phase U. The overvoltage event is triggered when the measured phase voltage is over the programmed voltage limit.";
CM_ SG_ 2147975174 Phase_W_undervoltage_0 "Indicates an undervoltage event on Phase U. The overvoltage event is triggered when the measured phase voltage is over the programmed voltage limit.";
CM_ SG_ 2147975174 Phase_W_overcurrent_0 "Indicates an overcurrent event on Phase U. The overcurrent event is triggered when the measured phase current is over the programmed current limit.";
CM_ SG_ 2147975174 DC_undervoltage_0 "DC bus undervoltage condition. The undervoltage condition is asserted when the measured dc bus voltage is under the programmed voltage limit.";
CM_ SG_ 2147975174 DC_overvoltage_0 "DC bus overvoltage condition. The overvoltage condition is asserted when the measured dc bus voltage is over the programmed voltage limit.";
CM_ SG_ 2147975174 MOSFET_overtemperature_0 "This flag is asserted when the temperature of the MOSFET block is too high.";
CM_ SG_ 2147975174 Inductor_overtemperature_0 "This flag is asserted when the temperature of the inductor block is too high.";
CM_ SG_ 2147975174 Keep_Alive_not_served_0 "The Keep Alive feature is enabled but it was not served with the periodic message.";
CM_ SG_ 2147975174 PLL_not_locked_0 "Flag asserted when in rectifier modes, the PLL went out of lock condition";
CM_ SG_ 2147975174 Measurement_system_failure_0 "The voltages/currents measurement system is malfunctionning, and readouts are not guaranteed to be accurate.";
CM_ SG_ 2147975174 EEPROM_failure_0 "The configuration EEPROM failed to load or save the module configuration.";
CM_ SG_ 2147975171 Phase_U_0 "Phase current is the MOSFET loop current, in the branch U of the converter.";
CM_ SG_ 2147975171 Phase_V_0 "Phase current is the MOSFET loop current, in the branch V of the converter.";
CM_ SG_ 2147975171 Phase_W_0 "Phase current is the MOSFET loop current, in the branch W of the converter.";
CM_ SG_ 2147975184 Bus_current_0 "DC Bus current is possitive when current goes from input to output";
CM_ SG_ 2147975182 Phase_U_0 "Phase current is the MOSFET loop current, in the branch U of the converter.";
CM_ SG_ 2147975182 Phase_V_0 "Phase current is the MOSFET loop current, in the branch V of the converter.";
CM_ SG_ 2147975182 Phase_W_0 "Phase current is the MOSFET loop current, in the branch W of the converter.";
CM_ SG_ 2147975182 Stack_position_0 "Sender Stack position";
CM_ SG_ 2147975182 Group_ID_0 "Sender Group ID";
CM_ SG_ 2147975179 Phase_U_0 "RMS Phase current is the MOSFET loop current, in the branch U of the converter.";
CM_ SG_ 2147975179 Phase_V_0 "RMS Phase current is the MOSFET loop current, in the branch V of the converter.";
CM_ SG_ 2147975179 Phase_W_0 "RMS Phase current is the MOSFET loop current, in the branch W of the converter.";
CM_ SG_ 2147975180 Frequency_0 "Frequency of Three-Phase system";
CM_ SG_ 2147975180 Phase_0 "Phase of Three-Phase system";
CM_ SG_ 2147975173 Temp_Bridge_0 "Temperature of the MOSFET block";
CM_ SG_ 2147975173 Temp_Inductors_0 "Temperature of the inductors";
CM_ SG_ 2147975176 Phase_U_0 "The actual PWM duty cycle setpoint";
CM_ SG_ 2147975176 Phase_V_0 "The actual PWM duty cycle setpoint";
CM_ SG_ 2147975176 Phase_W_0 "The actual PWM duty cycle setpoint";
CM_ SG_ 2147975177 Current_setpoint_0 "The actual current setpoint";
CM_ SG_ 2147975177 Voltage_setpoint_0 "The actual voltage setpoint";
CM_ SG_ 2147975177 Frequency_setpoint_0 "The actual frequency setpoint";
CM_ SG_ 2147942496 Keep_Alive_Enable_0 "If set to 1, module will expect to receive this message every second repeatedly, or it will stop operation";
CM_ SG_ 2147942464 Converter_ON_0 "Enable the converter.";
CM_ SG_ 2147942464 PWM_ON_0 "Enable the PWM control mode.";
CM_ SG_ 2147942464 DC_Current_feedback_ON_0 "Enable the DC current loop";
CM_ SG_ 2147942464 AC_Current_feedback_ON_0 "Enable the AC current loop";
CM_ SG_ 2147942464 Buck_ON_0 "Enable the buck control mode.";
CM_ SG_ 2147942464 Boost_ON_0 "Enable the boost control mode.";
CM_ SG_ 2147942464 Rectifier_3ph_ON_0 "Enable the three-phase rectifier control mode.";
CM_ SG_ 2147942464 Inverter_1ph_ON_0 "Enable the single-phase inverter control mode.";
CM_ SG_ 2147942464 Rectifier_1ph_ON_0 "Enable the single-phase rectifier control mode.";
CM_ SG_ 2147942464 Boost_Neutral_ON_0 "Enable the boost control mode with neutral generation.";
CM_ SG_ 2147942464 Inverter_3ph_ON_0 "Enable the three-phase inverter control mode.";
CM_ SG_ 2147942464 Inverter_1ph_Sync_ON_0 "Single-phase inverter control mode with phase synchronization.";
CM_ SG_ 2147942464 Neutral_ON_0 "Open-loop neutral generation.";
CM_ SG_ 2147942464 Rectifier_1ph_Buck_ON_0 "Single-phase rectifier with buck on one leg.";
CM_ SG_ 2147942464 Inverter_1ph_Boost_ON_0 "Single-phase inverter with boost on one leg.";
CM_ SG_ 2147942464 Rectifier_Distributed_ON_0 "Single-phase (floating) distributed rectifier";
CM_ SG_ 2147942464 MPPT_buck_ON_0 "MPPT buck";
CM_ SG_ 2147942464 MPPT_boost_ON_0 "MPPT boost";
CM_ SG_ 2147942464 Buck_2p_float_ON_0 "Boost on L1 and L2. Floating L3 (high-impedance)";
CM_ SG_ 2147942464 Inverter_1ph_Distributed_ON_0 "Single-phase inverter mode distributed";
CM_ SG_ 2147942480 Clear_Interlock_0 "Clears the converter interlock";
CM_ SG_ 2147942480 Reset_Processor_0 "Reset the converter DSP";
CM_ SG_ 2147942480 Trip_Interlock_0 "Trip the inetrnal Interlock";
CM_ SG_ 2147942465 Reactive_current_setpoint_0 "This defines reactive current setpoint for 3-phase rectifier mode";
CM_ SG_ 2147942466 Phase_U_0 "The actual PWM duty cycle setpoint";
CM_ SG_ 2147942466 Phase_V_0 "The actual PWM duty cycle setpoint";
CM_ SG_ 2147942466 Phase_W_0 "The actual PWM duty cycle setpoint";
CM_ SG_ 2147942467 Current_setpoint_0 "Sets the output current setpoint. Active only when the current loop is enabled";
CM_ SG_ 2147942468 Voltage_setpoint_0 "Sets the output voltage setpoint. Active only when the voltage loop is enabled";
CM_ SG_ 2147942472 Frequency_setpoint_0 "Sets the frequency for single-phase and three-phase generator modes.";
CM_ SG_ 2147942473 Phase_setpoint_0 "Sets the phase for inverter control modes.";
CM_ SG_ 2147942469 Stack_position_0 "The converter position within the stack";
CM_ SG_ 2147942469 Stack_size_0 "How many PFC converters are in stack in total";
CM_ SG_ 2147942469 SN_number_0 "Unique module serial number";
CM_ SG_ 2147942448 Phase_voltage_min_0 "Minimum tolerated phase voltage";
CM_ SG_ 2147942448 Phase_voltage_max_0 "Maximum allowable phase voltage";
CM_ SG_ 2147942448 DC_voltage_min_0 "Minimum allowable dc voltage";
CM_ SG_ 2147942448 DC_voltage_max_0 "Maximum allowable dc voltage";
CM_ SG_ 2147942449 Phase_current_min_0 "Minimum allowable output current";
CM_ SG_ 2147942449 Phase_current_max_0 "Maximum allowable output current";
CM_ SG_ 2147942476 Group_ID_0 "Desired group ID for the device";
CM_ SG_ 2147975183 Group_ID_0 "Group ID of the device";
CM_ SG_ 2147942497 Factory_mode_0 "Customers MUST NOT USE this bit. If set to 1, module will enter in factory mode. ";
CM_ SG_ 2147942497 Silent_CAN_mode_0 "Customers MUST NOT USE this bit. If set to 1, module will enter in factory mode. ";
CM_ SG_ 2147942474 start_0 "Start automatic calibration. Multiplexer index must be 0!";
CM_ SG_ 2147942475 point_0 "Calibration point index.";
CM_ SG_ 2147942470 CRC_0 "Checksum of bytes 0 to 3, CRC-CCITT, corresponding to qChecksum (www.qt.io)";
CM_ SG_ 2147942471 CRC_0 "Checksum of bytes 0 to 3, CRC-CCITT, corresponding to qChecksum (www.qt.io)";
CM_ SG_ 2147975254 Current_U_High_0 "This flag is set if a hight current on U tripped the internal interlock";
CM_ SG_ 2147975254 Current_U_Low_0 "This flag is set if a low current on U tripped the internal interlock";
CM_ SG_ 2147975254 Current_V_High_0 "This flag is set if a hight current on V tripped the internal interlock";
CM_ SG_ 2147975254 Current_V_Low_0 "This flag is set if a low current on V tripped the internal interlock";
CM_ SG_ 2147975254 Current_W_High_0 "This flag is set if a hight current on W tripped the internal interlock";
CM_ SG_ 2147975254 Current_W_Low_0 "This flag is set if a low current on W tripped the internal interlock";
CM_ SG_ 2147975254 Voltage_DC_0 "This flag is set if a voltage on DC tripped the internal interlock";
CM_ SG_ 2147975254 Reboot_0 "This flag is set if a reboot tripped the internal interlock";
CM_ SG_ 2147975254 Unknown_0 "This flag the reason for the internal interlock is unknown";

BA_DEF_ BO_ "SystemMessageLongSymbol" STRING;

BA_ "SystemMessageLongSymbol" BO_ 2147942465 "AFE_Reactive_Current_Setpoint_Control_0";

VAL_ 2147975168 Device_type_0 7 "AFE";
VAL_ 2147975174 Protection_trip_internal_0 1 "fault";
VAL_ 2147975174 Protection_trip_external_0 1 "fault";
VAL_ 2147975174 Phase_U_overcurrent_0 1 "fault";
VAL_ 2147975174 Phase_U_overvoltage_0 1 "fault";
VAL_ 2147975174 Phase_U_undervoltage_0 1 "fault";
VAL_ 2147975174 Phase_V_overvoltage_0 1 "fault";
VAL_ 2147975174 Phase_V_undervoltage_0 1 "fault";
VAL_ 2147975174 Phase_V_overcurrent_0 1 "fault";
VAL_ 2147975174 Phase_W_overvoltage_0 1 "fault";
VAL_ 2147975174 Phase_W_undervoltage_0 1 "fault";
VAL_ 2147975174 Phase_W_overcurrent_0 1 "fault";
VAL_ 2147975174 DC_undervoltage_0 1 "fault";
VAL_ 2147975174 DC_overvoltage_0 1 "fault";
VAL_ 2147975174 MOSFET_overtemperature_0 1 "fault";
VAL_ 2147975174 Inductor_overtemperature_0 1 "fault";
VAL_ 2147975174 Keep_Alive_not_served_0 1 "fault";
VAL_ 2147975174 PLL_not_locked_0 1 "fault";
VAL_ 2147975174 NFO_0 1 "fault";
VAL_ 2147975174 Measurement_system_failure_0 1 "fault";
VAL_ 2147975174 EEPROM_failure_0 1 "fault";
VAL_ 2147975174 System_0 1 "fault";
VAL_ 2147975254 Current_U_High_0 1 "fault";
VAL_ 2147975254 Current_U_Low_0 1 "fault";
VAL_ 2147975254 Current_V_High_0 1 "fault";
VAL_ 2147975254 Current_V_Low_0 1 "fault";
VAL_ 2147975254 Current_W_High_0 1 "fault";
VAL_ 2147975254 Current_W_Low_0 1 "fault";
VAL_ 2147975254 Voltage_DC_0 1 "fault";
VAL_ 2147975254 Reboot_0 1 "fault";
VAL_ 2147975254 Unknown_0 1 "fault";
SIG_VALTYPE_ 2147975249 Current_U_0 : 1;
SIG_VALTYPE_ 2147975249 Current_V_0 : 1;
SIG_VALTYPE_ 2147975249 Current_W_0 : 1;
SIG_VALTYPE_ 2147975249 Voltage_U_0 : 1;
SIG_VALTYPE_ 2147975249 Voltage_V_0 : 1;
SIG_VALTYPE_ 2147975249 Voltage_W_0 : 1;
SIG_VALTYPE_ 2147975249 Voltage_DC_0 : 1;
SIG_VALTYPE_ 2147975250 Current_U_0 : 1;
SIG_VALTYPE_ 2147975250 Current_V_0 : 1;
SIG_VALTYPE_ 2147975250 Current_W_0 : 1;
SIG_VALTYPE_ 2147975250 Voltage_U_0 : 1;
SIG_VALTYPE_ 2147975250 Voltage_V_0 : 1;
SIG_VALTYPE_ 2147975250 Voltage_W_0 : 1;
SIG_VALTYPE_ 2147975250 Voltage_DC_0 : 1;
